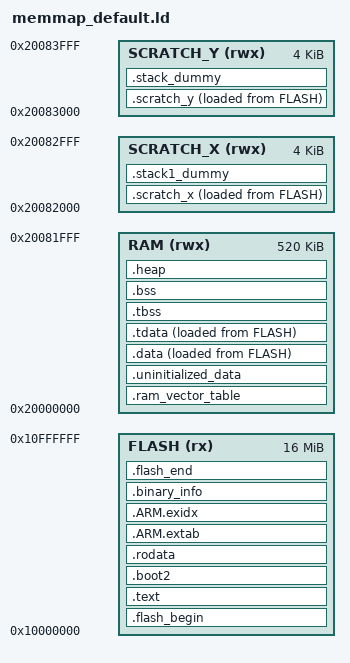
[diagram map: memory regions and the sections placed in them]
/****************************************************************************
 * boards/arm/rp23xx/picocalc-rp2350b/scripts/memmap_default.ld
 *
 * Linker script for PicoCalc RP2350B-Plus-W
 *   - Waveshare RP2350B-Plus-W: 16 MB flash, 520 KB SRAM
 *   - Based on raspberrypi-pico-2 memmap_default.ld
 *
 ****************************************************************************/

/* Defines the following symbols for use by code:
    __exidx_start
    __exidx_end
    __etext
    __data_start__
    __preinit_array_start
    __preinit_array_end
    __init_array_start
    __init_array_end
    __fini_array_start
    __fini_array_end
    __data_end__
    __bss_start__
    __bss_end__
    __end__
    end
    __HeapLimit
    __StackLimit
    __StackTop
    __stack (== StackTop)
*/

MEMORY
{
    FLASH(rx)      : ORIGIN = 0x10000000, LENGTH = 16384k
    RAM(rwx)       : ORIGIN = 0x20000000, LENGTH = 520k
    SCRATCH_X(rwx) : ORIGIN = 0x20082000, LENGTH = 4k
    SCRATCH_Y(rwx) : ORIGIN = 0x20083000, LENGTH = 4k
}

ENTRY(_entry_point)

SECTIONS
{
    .flash_begin : {
        __flash_binary_start = .;
    } > FLASH

    /* The bootrom will enter the image at the point indicated in your
       IMAGE_DEF, which is usually the reset handler of your vector table.

       The debugger will use the ELF entry point, which is the _entry_point
       symbol, and in our case is *different from the bootrom's entry point.*
       This is used to go back through the bootrom on debugger launches only,
       to perform the same initial flash setup that would be performed on a
       cold boot.
    */

    .text : {
        __logical_binary_start = .;
        _stext = ABSOLUTE(.);

        KEEP (*(.vectors))

        /* RP2350 IMAGE_DEF block — required by bootrom */
        LONG(0xffffded3)
        LONG(0x10210142)
        LONG(0x000001ff)
        LONG(0x00000000)
        LONG(0xab123579)

        KEEP (*(.binary_info_header))
        __binary_info_header_end = .;
        KEEP (*(.embedded_block))
        __embedded_block_end = .;
        KEEP (*(.reset))

        /* Exclude memset/memcpy etc from flash for performance */
        *(.init)
        *libgcc.a:cmse_nonsecure_call.o
        *(EXCLUDE_FILE(*libgcc.a: *libc.a:*lib_a-mem*.o *libm.a:) .text*)
        *(.fini)

        /* Pull all c'tors into .text */
        *crtbegin.o(.ctors)
        *crtbegin?.o(.ctors)
        *(EXCLUDE_FILE(*crtend?.o *crtend.o) .ctors)
        *(SORT(.ctors.*))
        *(.ctors)
        /* Followed by destructors */
        *crtbegin.o(.dtors)
        *crtbegin?.o(.dtors)
        *(EXCLUDE_FILE(*crtend?.o *crtend.o) .dtors)
        *(SORT(.dtors.*))
        *(.dtors)

        . = ALIGN(4);
        /* preinit data */
        PROVIDE_HIDDEN (__preinit_array_start = .);
        KEEP(*(SORT(.preinit_array.*)))
        KEEP(*(.preinit_array))
        PROVIDE_HIDDEN (__preinit_array_end = .);

        . = ALIGN(4);
        /* init data */
        PROVIDE_HIDDEN (__init_array_start = .);
        KEEP(*(SORT(.init_array.*)))
        KEEP(*(.init_array))
        PROVIDE_HIDDEN (__init_array_end = .);

        . = ALIGN(4);
        /* finit data */
        PROVIDE_HIDDEN (__fini_array_start = .);
        *(SORT(.fini_array.*))
        *(.fini_array)
        PROVIDE_HIDDEN (__fini_array_end = .);

        *(.eh_frame*)
        . = ALIGN(4);
        _etext = ABSOLUTE(.);
    } > FLASH

    /* Optional boot2 XIP setup function — size limit 256 bytes */

    .boot2 : {
        __boot2_start__ = .;
        *(.boot2)
        __boot2_end__ = .;
    } > FLASH

    ASSERT(__boot2_end__ - __boot2_start__ <= 256,
        "ERROR: Pico second stage bootloader must be no more than 256 bytes in size")

    .rodata : {
        *(EXCLUDE_FILE(*libgcc.a: *libc.a:*lib_a-mem*.o *libm.a:) .rodata*)
        *(.srodata*)
        . = ALIGN(4);
        *(SORT_BY_ALIGNMENT(SORT_BY_NAME(.flashdata*)))
        . = ALIGN(4);
    } > FLASH

    .ARM.extab :
    {
        *(.ARM.extab* .gnu.linkonce.armextab.*)
    } > FLASH

    __exidx_start = .;
    .ARM.exidx :
    {
        *(.ARM.exidx* .gnu.linkonce.armexidx.*)
    } > FLASH
    __exidx_end = .;

    /* Machine inspectable binary information */
    . = ALIGN(4);
    __binary_info_start = .;
    .binary_info :
    {
        KEEP(*(.binary_info.keep.*))
        *(.binary_info.*)
    } > FLASH
    _eronly = ABSOLUTE(.);
    __binary_info_end = .;
    . = ALIGN(4);

    .ram_vector_table (NOLOAD): {
        *(.ram_vector_table)
    } > RAM

    .uninitialized_data (NOLOAD): {
        . = ALIGN(4);
        *(.uninitialized_data*)
    } > RAM

    .data : {
        __data_start__ = .;
        _sdata = ABSOLUTE(.);

        *(vtable)

        *(.time_critical*)

        /* remaining .text and .rodata; i.e. stuff we exclude above
           because we want it in RAM */
        *(.text*)
        . = ALIGN(4);
        *(.rodata*)
        . = ALIGN(4);

        *(.data*)
        *(.sdata*)

        . = ALIGN(4);
        *(.after_data.*)
        . = ALIGN(4);

        /* mutex array */
        PROVIDE_HIDDEN (__mutex_array_start = .);
        KEEP(*(SORT(.mutex_array.*)))
        KEEP(*(.mutex_array))
        PROVIDE_HIDDEN (__mutex_array_end = .);

        *(.jcr)
        . = ALIGN(4);
        _edata = ABSOLUTE(.);
    } > RAM AT> FLASH

    .tdata : {
        _stdata = ABSOLUTE(.);
        . = ALIGN(4);
        *(.tdata .tdata.* .gnu.linkonce.td.*)
        __tdata_end = .;
        _etdata = ABSOLUTE(.);
    } > RAM AT> FLASH
    PROVIDE(__data_end__ = .);

    __etext = LOADADDR(.data);

    .tbss (NOLOAD) : {
        _stbss = ABSOLUTE(.);
        . = ALIGN(4);
        __bss_start__ = .;
        _sbss = ABSOLUTE(.);
        __tls_base = .;
        *(.tbss .tbss.* .gnu.linkonce.tb.*)
        *(.tcommon)

        __tls_end = .;
        _etbss = ABSOLUTE(.);
    } > RAM

    .bss (NOLOAD) : {
        . = ALIGN(4);
        __tbss_end = .;

        *(SORT_BY_ALIGNMENT(SORT_BY_NAME(.bss*)))
        *(COMMON)
        PROVIDE(__global_pointer$ = . + 2K);
        *(.sbss*)
        . = ALIGN(4);
        __bss_end__ = .;
        _ebss = ABSOLUTE(.);
    } > RAM

    .heap (NOLOAD):
    {
        __end__ = .;
        end = __end__;
        _sheap = .;
        KEEP(*(.heap*))
    } > RAM
    __HeapLimit = ORIGIN(RAM) + LENGTH(RAM);
    _eheap = __HeapLimit;

    /* Start and end symbols must be word-aligned */
    .scratch_x : {
        __scratch_x_start__ = .;
        *(.scratch_x.*)
        . = ALIGN(4);
        __scratch_x_end__ = .;
    } > SCRATCH_X AT > FLASH
    __scratch_x_source__ = LOADADDR(.scratch_x);

    .scratch_y : {
        __scratch_y_start__ = .;
        *(.scratch_y.*)
        . = ALIGN(4);
        __scratch_y_end__ = .;
    } > SCRATCH_Y AT > FLASH
    __scratch_y_source__ = LOADADDR(.scratch_y);

    .stack1_dummy (NOLOAD):
    {
        *(.stack1*)
    } > SCRATCH_X
    .stack_dummy (NOLOAD):
    {
        KEEP(*(.stack*))
    } > SCRATCH_Y

    .flash_end : {
        KEEP(*(.embedded_end_block*))
        PROVIDE(__flash_binary_end = .);
    } > FLASH =0xaa

    /* stack limit is poorly named, but historically is maximum heap ptr */
    __StackLimit = ORIGIN(RAM) + LENGTH(RAM);
    __StackOneTop = ORIGIN(SCRATCH_X) + LENGTH(SCRATCH_X);
    __StackTop = ORIGIN(SCRATCH_Y) + LENGTH(SCRATCH_Y);
    __StackOneBottom = __StackOneTop - SIZEOF(.stack1_dummy);
    __StackBottom = __StackTop - SIZEOF(.stack_dummy);
    PROVIDE(__stack = __StackTop);

    /* picolibc and LLVM */
    PROVIDE (__heap_start = __end__);
    PROVIDE (__heap_end = __HeapLimit);
    PROVIDE( __tls_align = MAX(ALIGNOF(.tdata), ALIGNOF(.tbss)) );
    PROVIDE( __tls_size_align = (__tls_size + __tls_align - 1) & ~(__tls_align - 1));
    PROVIDE( __arm32_tls_tcb_offset = MAX(8, __tls_align) );

    /* llvm-libc */
    PROVIDE (_end = __end__);
    PROVIDE (__llvm_libc_heap_limit = __HeapLimit);

    /* Check if data + heap + stack exceeds RAM limit */
    ASSERT(__StackLimit >= __HeapLimit, "region RAM overflowed")

    ASSERT( __binary_info_header_end - __logical_binary_start <= 1024, "Binary info must be in first 1024 bytes of the binary")
    ASSERT( __embedded_block_end - __logical_binary_start <= 4096, "Embedded block must be in first 4096 bytes of the binary")
}
